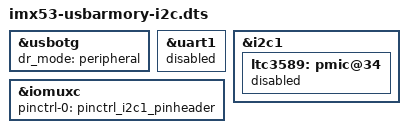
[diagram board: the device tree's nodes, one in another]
/*
 * USB armory MkI device mode device tree file
 * https://inversepath.com/usbarmory
 *
 * Copyright (C) 2015, Inverse Path
 * Andrej Rosano <andrej@inversepath.com>
 *
 * Licensed under GPLv2
 */

/dts-v1/;

#include "imx53-usbarmory-common.dtsi"

&usbotg {
	dr_mode = "peripheral";
	status = "okay";
};

&uart1 {
	status = "disabled";
};

&iomuxc {
	pinctrl-0 = <&pinctrl_i2c1_pinheader>;
};

&i2c1 {
	ltc3589: pmic@34 {
		status = "disabled";
	};
};
